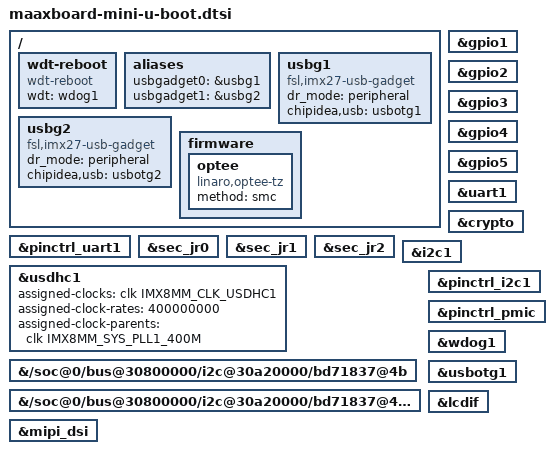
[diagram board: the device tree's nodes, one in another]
/*
 * Copyright 2022 AVNET
 *
 * This program is free software; you can redistribute it and/or
 * modify it under the terms of the GNU General Public License
 * as published by the Free Software Foundation; either version 2
 * of the License, or (at your option) any later version.
 *
 * This program is distributed in the hope that it will be useful,
 * but WITHOUT ANY WARRANTY; without even the implied warranty of
 * MERCHANTABILITY or FITNESS FOR A PARTICULAR PURPOSE.  See the
 * GNU General Public License for more details.
 */

#include "imx8mm-u-boot.dtsi"

/ {

	wdt-reboot {
		compatible = "wdt-reboot";
		wdt = <&wdog1>;
		u-boot,dm-spl;
	};

	aliases {
		usbgadget0 = &usbg1;
		usbgadget1 = &usbg2;
	};

	usbg1: usbg1 {
		compatible = "fsl,imx27-usb-gadget";
		dr_mode = "peripheral";
		chipidea,usb = <&usbotg1>;
		status = "okay";
	};

	usbg2: usbg2 {
		compatible = "fsl,imx27-usb-gadget";
		dr_mode = "peripheral";
		chipidea,usb = <&usbotg2>;
		status = "okay";
	};

	firmware {
		optee {
			compatible = "linaro,optee-tz";
			method = "smc";
		};
	};
};

&pinctrl_uart1 {
	u-boot,dm-spl;
};

&gpio1 {
	u-boot,dm-spl;
};

&gpio2 {
	u-boot,dm-spl;
};

&gpio3 {
	u-boot,dm-spl;
};

&gpio4 {
	u-boot,dm-spl;
};

&gpio5 {
	u-boot,dm-spl;
};

&uart1 {
	u-boot,dm-spl;
};

&crypto {
	u-boot,dm-spl;
};

&sec_jr0 {
	u-boot,dm-spl;
};

&sec_jr1 {
	u-boot,dm-spl;
};

&sec_jr2 {
	u-boot,dm-spl;
};

&usdhc1 {
	u-boot,dm-spl;
	assigned-clocks = <&clk IMX8MM_CLK_USDHC1>;
	assigned-clock-rates = <400000000>;
	assigned-clock-parents = <&clk IMX8MM_SYS_PLL1_400M>;
};

&i2c1 {
	u-boot,dm-spl;
};

&{/soc@0/bus@30800000/i2c@30a20000/bd71837@4b} {
	u-boot,dm-spl;
};

&{/soc@0/bus@30800000/i2c@30a20000/bd71837@4b/regulators} {
	u-boot,dm-spl;
};

&pinctrl_i2c1 {
	u-boot,dm-spl;
};

&pinctrl_pmic {
	u-boot,dm-spl;
};

&wdog1 {
	u-boot,dm-spl;
};

&usbotg1 {
	status = "okay";
};

&lcdif {
	/delete-property/ assigned-clocks;
	/delete-property/ assigned-clock-parents;
	/delete-property/ assigned-clock-rates;
};

&mipi_dsi {
	/delete-property/ assigned-clocks;
	/delete-property/ assigned-clock-parents;
	/delete-property/ assigned-clock-rates;
};
